# CBASS_INFRA0_ERR register map
Vendor: Texas Instruments
Peripheral module from a debugger description file (folder J7ES).
Registers are 32-bit, read-only, reset 0x0 unless marked. A register's access mark holds for its fields unless they carry their own. Offsets are as the file gives them; lines under a group give offsets from that group; [hi:lo] are bit positions; {n}, {i} and the like mark numbered series; 'fields as' and 'values as' point back to an identical list; <NAME> marks a mode.

## CBASS_INFRA0_ERR
0x00 CBASS_PID reset not defined — The Revision Register contains the major and minor revisions for the module.
  [31:0] REV — TI internal data.
0x04 CBASS_DESTINATION_ID rw — The Destination ID Register defines the destination ID value for error messages.
  [7:0] DEST_ID — The destination ID.
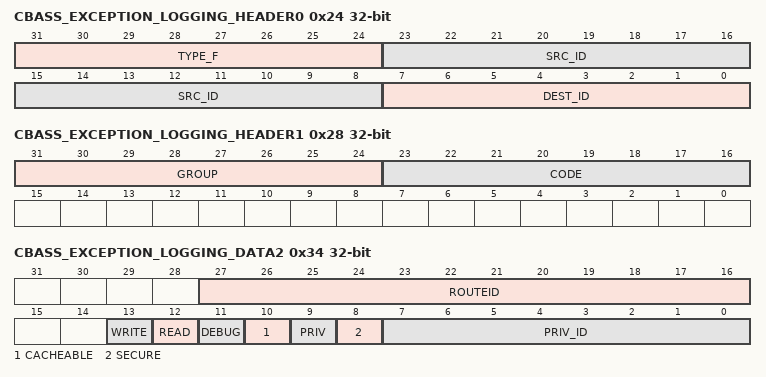
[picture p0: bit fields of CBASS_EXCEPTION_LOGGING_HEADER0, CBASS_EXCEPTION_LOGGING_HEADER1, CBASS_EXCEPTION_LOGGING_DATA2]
0x24 CBASS_EXCEPTION_LOGGING_HEADER0 — The Exception Logging Header 0 Register contains the first word of the header.
  [31:24] TYPE_F — Type.
  [23:8] SRC_ID — Source ID.
  [7:0] DEST_ID — Destination ID.
0x28 CBASS_EXCEPTION_LOGGING_HEADER1 — The Exception Logging Header 1 Register contains the second word of the header.
  [31:24] GROUP, [23:16] CODE
0x2C CBASS_EXCEPTION_LOGGING_DATA0 — The Exception Logging Data 0 Register contains the first word of the data.
  [31:0] ADDR_L — Address lower 32 bits.
0x30 CBASS_EXCEPTION_LOGGING_DATA1 — The Exception Logging Data 1 Register contains the second word of the data.
  [15:0] ADDR_H — Address upper 16 bits.
0x34 CBASS_EXCEPTION_LOGGING_DATA2 — The Exception Logging Data 2 Register contains the third word of the data.
  [27:16] ROUTEID, [13] WRITE, [12] READ, [11] DEBUG, [10] CACHEABLE, [9] PRIV, [8] SECURE, [7:0] PRIV_ID
0x38 CBASS_EXCEPTION_LOGGING_DATA3 — The Exception Logging Data 3 Register contains the fourth word of the data.
  [9:0] BYTECNT — Byte count.
0x50 CBASS_ERR_INTR_RAW_STAT access not given — Global Interrupt Raw Status Register
  [0] INTR — Level Interrupt status (access RW1S)
0x54 CBASS_ERR_INTR_ENABLED_STAT access not given — Global Interrupt Enabled Status Register
  [0] ENABLED_INTR — Level Enabled Interrupt status (access RW1C)
0x58 CBASS_ERR_INTR_ENABLE_SET access not given — Interrupt Enable Set Register
  [0] INTR_ENABLE_SET — Interrupt Enable Set Register (access RW1S)
0x5C CBASS_ERR_INTR_ENABLE_CLR access not given — Interrupt Enable Clear Register
  [0] INTR_ENABLE_CLR — Interrupt Enable Clear Register (access RW1C)
0x60 CBASS_EOI rw — End of Interrupt Register
  [15:0] WR
